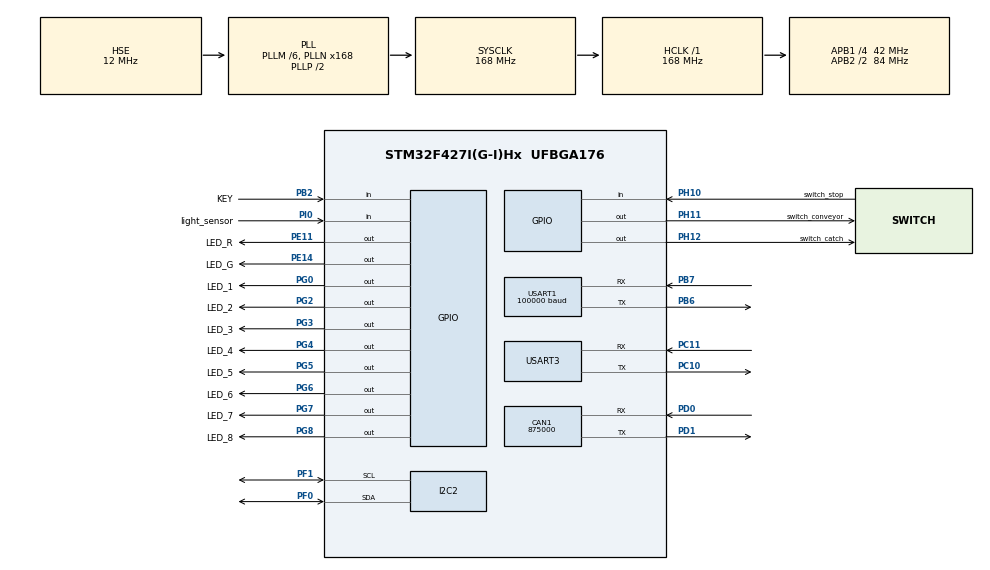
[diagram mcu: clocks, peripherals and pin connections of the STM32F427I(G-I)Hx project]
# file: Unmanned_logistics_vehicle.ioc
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CAN1.CalculateBaudRate=875000
CAN1.CalculateTimeBit=1142.85
CAN1.CalculateTimeQuantum=380.95238095238096
Dma.Request0=USART1_RX
Dma.Request1=USART3_TX
Dma.USART1_RX.0.Direction=DMA_PERIPH_TO_MEMORY
Dma.USART1_RX.0.FIFOMode=DMA_FIFOMODE_DISABLE
Dma.USART1_RX.0.Instance=DMA2_Stream2
Dma.USART1_RX.0.MemDataAlignment=DMA_MDATAALIGN_BYTE
Dma.USART1_RX.0.MemInc=DMA_MINC_ENABLE
Dma.USART1_RX.0.Mode=DMA_NORMAL
Dma.USART1_RX.0.PeriphDataAlignment=DMA_PDATAALIGN_BYTE
Dma.USART1_RX.0.PeriphInc=DMA_PINC_DISABLE
Dma.USART1_RX.0.Priority=DMA_PRIORITY_VERY_HIGH
Dma.USART3_TX.1.Direction=DMA_MEMORY_TO_PERIPH
Dma.USART3_TX.1.FIFOMode=DMA_FIFOMODE_DISABLE
Dma.USART3_TX.1.Instance=DMA1_Stream3
Dma.USART3_TX.1.MemDataAlignment=DMA_MDATAALIGN_BYTE
Dma.USART3_TX.1.MemInc=DMA_MINC_ENABLE
Dma.USART3_TX.1.Mode=DMA_NORMAL
Dma.USART3_TX.1.PeriphDataAlignment=DMA_PDATAALIGN_BYTE
Dma.USART3_TX.1.PeriphInc=DMA_PINC_DISABLE
Dma.USART3_TX.1.Priority=DMA_PRIORITY_VERY_HIGH
FREERTOS.Tasks01=testTask,0,128,test_task,As weak,NULL,Dynamic,NULL,NULL;armTask,-3,512,arm_task,As weak,NULL,Dynamic,NULL,NULL;conveyorTask,-3,128,conveyor_task,As weak,NULL,Dynamic,NULL,NULL;detectTask,-3,128,detect_task,As weak,NULL,Dynamic,NULL,NULL;interactiveTask,-3,128,interactive_task,As weak,NULL,Dynamic,NULL,NULL
I2C2.I2C_Mode=I2C_Fast
Mcu.Family=STM32F4
Mcu.Name=STM32F427I(G-I)Hx
Mcu.Package=UFBGA176
NVIC.CAN1_RX0_IRQn=true\:5\:0\:false\:false\:true\:true\:true\:true
NVIC.DMA1_Stream3_IRQn=true\:5\:0\:false\:false\:true\:true\:false\:true
NVIC.DMA2_Stream2_IRQn=true\:5\:0\:false\:false\:true\:true\:false\:true
NVIC.PriorityGroup=NVIC_PRIORITYGROUP_4
NVIC.USART1_IRQn=true\:5\:0\:false\:false\:true\:true\:true\:true
NVIC.USART3_IRQn=true\:5\:0\:false\:false\:true\:true\:true\:true
PB2/BOOT1.GPIO_Label=KEY
PB2/BOOT1.Signal=GPIO_Input
PB6.GPIO_PuPd=GPIO_PULLUP
PB6.Mode=Asynchronous
PB6.Signal=USART1_TX
PB7.GPIO_PuPd=GPIO_PULLUP
PB7.Mode=Asynchronous
PB7.Signal=USART1_RX
PC10.Mode=Asynchronous
PC10.Signal=USART3_TX
PC11.Mode=Asynchronous
PC11.Signal=USART3_RX
PD0.Mode=CAN_Activate
PD0.Signal=CAN1_RX
PD1.Mode=CAN_Activate
PD1.Signal=CAN1_TX
PE11.GPIO_Label=LED_R
PE11.Signal=GPIO_Output
PE14.GPIO_Label=LED_G
PE14.Signal=GPIO_Output
PF0.Mode=I2C
PF0.Signal=I2C2_SDA
PF1.Mode=I2C
PF1.Signal=I2C2_SCL
PG0.GPIO_Label=LED_1
PG0.Signal=GPIO_Output
PG2.GPIO_Label=LED_2
PG2.Signal=GPIO_Output
PG3.GPIO_Label=LED_3
PG3.Signal=GPIO_Output
PG4.GPIO_Label=LED_4
PG4.Signal=GPIO_Output
PG5.GPIO_Label=LED_5
PG5.Signal=GPIO_Output
PG6.GPIO_Label=LED_6
PG6.Signal=GPIO_Output
PG7.GPIO_Label=LED_7
PG7.Signal=GPIO_Output
PG8.GPIO_Label=LED_8
PG8.Signal=GPIO_Output
PH0/OSC_IN.Mode=HSE-External-Oscillator
PH0/OSC_IN.Signal=RCC_OSC_IN
PH1/OSC_OUT.Mode=HSE-External-Oscillator
PH1/OSC_OUT.Signal=RCC_OSC_OUT
PH10.GPIO_Label=switch_stop
PH10.Signal=GPIO_Input
PH11.GPIO_Label=switch_conveyor
PH11.Signal=GPIO_Output
PH12.GPIO_Label=switch_catch
PH12.Signal=GPIO_Output
PI0.GPIO_Label=light_sensor
PI0.Signal=GPIO_Input
ProjectManager.HeapSize=0x200
ProjectManager.StackSize=0x400
ProjectManager.TargetToolchain=MDK-ARM V5.27
RCC.48MHZClocksFreq_Value=84000000
RCC.AHBFreq_Value=168000000
RCC.APB1CLKDivider=RCC_HCLK_DIV4
RCC.APB1Freq_Value=42000000
RCC.APB1TimFreq_Value=84000000
RCC.APB2CLKDivider=RCC_HCLK_DIV2
RCC.APB2Freq_Value=84000000
RCC.APB2TimFreq_Value=168000000
RCC.CortexFreq_Value=168000000
RCC.HCLKFreq_Value=168000000
RCC.HSE_VALUE=12000000
RCC.HSI_VALUE=16000000
RCC.LSE_VALUE=32768
RCC.PLLM=6
RCC.PLLN=168
RCC.PLLSourceVirtual=RCC_PLLSOURCE_HSE
RCC.SYSCLKFreq_VALUE=168000000
RCC.SYSCLKSource=RCC_SYSCLKSOURCE_PLLCLK
RCC.VCOOutputFreq_Value=336000000
USART1.BaudRate=100000
USART1.Mode=MODE_RX
USART1.Parity=PARITY_EVEN
USART1.VirtualMode=VM_ASYNC
USART3.VirtualMode=VM_ASYNC
VP_FREERTOS_VS_CMSIS_V1.Mode=CMSIS_V1
board=custom

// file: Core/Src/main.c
/* USER CODE BEGIN Header */
/**
  ******************************************************************************
  * @file           : main.c
  * @brief          : Main program body
  ******************************************************************************
  * @attention
  *
  * <h2><center>&copy; Copyright (c) 2021 STMicroelectronics.
  * All rights reserved.</center></h2>
  *
  * This software component is licensed by ST under Ultimate Liberty license
  * SLA0044, the "License"; You may not use this file except in compliance with
  * the License. You may obtain a copy of the License at:
  *                             www.st.com/SLA0044
  *
  ******************************************************************************
  */
/* USER CODE END Header */
#include "main.h"
#include "cmsis_os.h"
#include "can.h"
#include "dma.h"
#include "i2c.h"
#include "usart.h"
#include "gpio.h"

/* USER CODE BEGIN Includes */
#include "remote_control.h"
#include "CAN_receive.h"
#include "OLED.h"
/* USER CODE END Includes */

void SystemClock_Config(void);
void MX_FREERTOS_Init(void);

int main(void)
{

  /* MCU Configuration--------------------------------------------------------*/

  /* Reset of all peripherals, Initializes the Flash interface and the Systick. */
  HAL_Init();

  /* Configure the system clock */
  SystemClock_Config();

  /* Initialize all configured peripherals */
  MX_GPIO_Init();
  MX_DMA_Init();
  MX_USART1_UART_Init();
  MX_USART3_UART_Init();
  MX_I2C2_Init();
  MX_CAN1_Init();
  /* USER CODE BEGIN 2 */
	can_filter_init();
  remote_control_init();
  /* USER CODE END 2 */

  /* Call init function for freertos objects (in freertos.c) */
  MX_FREERTOS_Init();
  /* Start scheduler */
  osKernelStart();

  /* We should never get here as control is now taken by the scheduler */
  /* Infinite loop */
  while (1)
  {

    /* USER CODE BEGIN 3 */
		HAL_Delay(200);
  }
  /* USER CODE END 3 */
}

void SystemClock_Config(void)
{
  RCC_OscInitTypeDef RCC_OscInitStruct = {0};
  RCC_ClkInitTypeDef RCC_ClkInitStruct = {0};

  /** Configure the main internal regulator output voltage
  */
  __HAL_RCC_PWR_CLK_ENABLE();
  __HAL_PWR_VOLTAGESCALING_CONFIG(PWR_REGULATOR_VOLTAGE_SCALE1);
  /** Initializes the RCC Oscillators according to the specified parameters
  * in the RCC_OscInitTypeDef structure.
  */
  RCC_OscInitStruct.OscillatorType = RCC_OSCILLATORTYPE_HSE;
  RCC_OscInitStruct.HSEState = RCC_HSE_ON;
  RCC_OscInitStruct.PLL.PLLState = RCC_PLL_ON;
  RCC_OscInitStruct.PLL.PLLSource = RCC_PLLSOURCE_HSE;
  RCC_OscInitStruct.PLL.PLLM = 6;
  RCC_OscInitStruct.PLL.PLLN = 168;
  RCC_OscInitStruct.PLL.PLLP = RCC_PLLP_DIV2;
  RCC_OscInitStruct.PLL.PLLQ = 4;
  if (HAL_RCC_OscConfig(&RCC_OscInitStruct) != HAL_OK)
  {
    Error_Handler();
  }
  /** Initializes the CPU, AHB and APB buses clocks
  */
  RCC_ClkInitStruct.ClockType = RCC_CLOCKTYPE_HCLK|RCC_CLOCKTYPE_SYSCLK
                              |RCC_CLOCKTYPE_PCLK1|RCC_CLOCKTYPE_PCLK2;
  RCC_ClkInitStruct.SYSCLKSource = RCC_SYSCLKSOURCE_PLLCLK;
  RCC_ClkInitStruct.AHBCLKDivider = RCC_SYSCLK_DIV1;
  RCC_ClkInitStruct.APB1CLKDivider = RCC_HCLK_DIV4;
  RCC_ClkInitStruct.APB2CLKDivider = RCC_HCLK_DIV2;

  if (HAL_RCC_ClockConfig(&RCC_ClkInitStruct, FLASH_LATENCY_5) != HAL_OK)
  {
    Error_Handler();
  }
}

void Error_Handler(void)
{
  __disable_irq();
  while (1)
  {
  }
}

/************************ (C) COPYRIGHT STMicroelectronics *****END OF FILE****/

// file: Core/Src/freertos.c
/* USER CODE BEGIN Header */
/**
  ******************************************************************************
  * File Name          : freertos.c
  * Description        : Code for freertos applications
  ******************************************************************************
  * @attention
  *
  * <h2><center>&copy; Copyright (c) 2021 STMicroelectronics.
  * All rights reserved.</center></h2>
  *
  * This software component is licensed by ST under Ultimate Liberty license
  * SLA0044, the "License"; You may not use this file except in compliance with
  * the License. You may obtain a copy of the License at:
  *                             www.st.com/SLA0044
  *
  ******************************************************************************
  */
/* USER CODE END Header */

#include "FreeRTOS.h"
#include "task.h"
#include "main.h"
#include "cmsis_os.h"

osThreadId testTaskHandle;
osThreadId armTaskHandle;
osThreadId conveyorTaskHandle;
osThreadId detectTaskHandle;
osThreadId interactiveTaskHandle;

void test_task(void const * argument);
void arm_task(void const * argument);
void conveyor_task(void const * argument);
void detect_task(void const * argument);
void interactive_task(void const * argument);

void MX_FREERTOS_Init(void); /* (MISRA C 2004 rule 8.1) */

/* GetIdleTaskMemory prototype (linked to static allocation support) */
void vApplicationGetIdleTaskMemory( StaticTask_t **ppxIdleTaskTCBBuffer, StackType_t **ppxIdleTaskStackBuffer, uint32_t *pulIdleTaskStackSize );

/* USER CODE BEGIN GET_IDLE_TASK_MEMORY */
static StaticTask_t xIdleTaskTCBBuffer;
static StackType_t xIdleStack[configMINIMAL_STACK_SIZE];

void vApplicationGetIdleTaskMemory( StaticTask_t **ppxIdleTaskTCBBuffer, StackType_t **ppxIdleTaskStackBuffer, uint32_t *pulIdleTaskStackSize )
{
  *ppxIdleTaskTCBBuffer = &xIdleTaskTCBBuffer;
  *ppxIdleTaskStackBuffer = &xIdleStack[0];
  *pulIdleTaskStackSize = configMINIMAL_STACK_SIZE;
  /* place for user code */
}
/* USER CODE END GET_IDLE_TASK_MEMORY */

void MX_FREERTOS_Init(void) {

  /* Create the thread(s) */
  /* definition and creation of testTask */
  osThreadDef(testTask, test_task, osPriorityNormal, 0, 128);
  testTaskHandle = osThreadCreate(osThread(testTask), NULL);

  /* definition and creation of armTask */
  osThreadDef(armTask, arm_task, osPriorityIdle, 0, 512);
  armTaskHandle = osThreadCreate(osThread(armTask), NULL);

  /* definition and creation of conveyorTask */
  osThreadDef(conveyorTask, conveyor_task, osPriorityIdle, 0, 128);
  conveyorTaskHandle = osThreadCreate(osThread(conveyorTask), NULL);

  /* definition and creation of detectTask */
  osThreadDef(detectTask, detect_task, osPriorityIdle, 0, 128);
  detectTaskHandle = osThreadCreate(osThread(detectTask), NULL);

  /* definition and creation of interactiveTask */
  osThreadDef(interactiveTask, interactive_task, osPriorityIdle, 0, 128);
  interactiveTaskHandle = osThreadCreate(osThread(interactiveTask), NULL);

}

__weak void test_task(void const * argument)
{
  for(;;)
  {
    osDelay(1);
  }
}

__weak void arm_task(void const * argument)
{
  for(;;)
  {
    osDelay(1);
  }
}

__weak void conveyor_task(void const * argument)
{
  for(;;)
  {
    osDelay(1);
  }
}

__weak void detect_task(void const * argument)
{
  for(;;)
  {
    osDelay(1);
  }
}

__weak void interactive_task(void const * argument)
{
  for(;;)
  {
    osDelay(1);
  }
}

/************************ (C) COPYRIGHT STMicroelectronics *****END OF FILE****/
